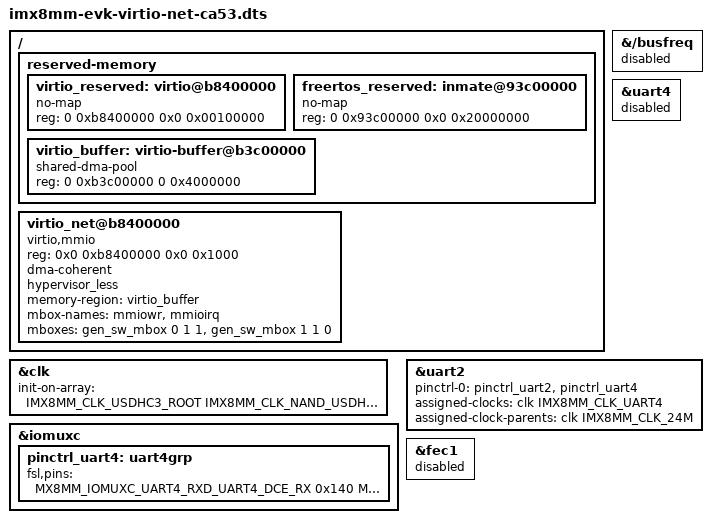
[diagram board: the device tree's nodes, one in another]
// SPDX-License-Identifier: (GPL-2.0 OR MIT)
/*
 * Copyright 2023 NXP
 */

/dts-v1/;
#include "imx8mm-evk.dts"
#include "imx8m-generic-mbox.dtsi"

/ {
	reserved-memory {
		#address-cells = <2>;
		#size-cells = <2>;
		ranges;

		virtio_reserved: virtio@b8400000 {
			no-map;
			reg = <0 0xb8400000 0x0 0x00100000>;
		};

		/* 512MB */
		freertos_reserved: inmate@93c00000 {
			no-map;
			reg = <0 0x93c00000 0x0 0x20000000>;
		};

		virtio_buffer: virtio-buffer@b3c00000 {
			compatible = "shared-dma-pool";
			reg = <0 0xb3c00000 0 0x4000000>;
		};
	};

	virtio_net@b8400000 {
		compatible = "virtio,mmio";
		reg = <0x0 0xb8400000 0x0 0x1000>;
		dma-coherent;
		hypervisor_less;
		memory-region = <&virtio_buffer>;
		mbox-names = "mmiowr", "mmioirq";
		mboxes = <&gen_sw_mbox 0 1 1		/* TX channel with ACK */
			  &gen_sw_mbox 1 1 0>;		/* RX channel without ACK */
	};
};

&{/busfreq} {
	/* Disable busfreq to avoid Linux busfreq crash multicore virtio backend */
	status = "disabled";
};

&uart4 {
	status = "disabled";
};

&clk {
	init-on-array = <IMX8MM_CLK_USDHC3_ROOT
			IMX8MM_CLK_NAND_USDHC_BUS
			IMX8MM_CLK_UART4_ROOT>;
};

&iomuxc {
	/*
	 * Used for the 2nd Linux.
	 * TODO: M4 may use these pins.
	 */
	pinctrl_uart4: uart4grp {
		fsl,pins = <
			MX8MM_IOMUXC_UART4_RXD_UART4_DCE_RX	0x140
			MX8MM_IOMUXC_UART4_TXD_UART4_DCE_TX	0x140
		>;
	};
};

&uart2 {
	/* uart2 is used by the 2nd OS, so configure pin and clk */
	pinctrl-0 = <&pinctrl_uart2>, <&pinctrl_uart4>;
	assigned-clocks = <&clk IMX8MM_CLK_UART4>;
	assigned-clock-parents = <&clk IMX8MM_CLK_24M>;
};

&fec1 {
	status = "disabled";
};
